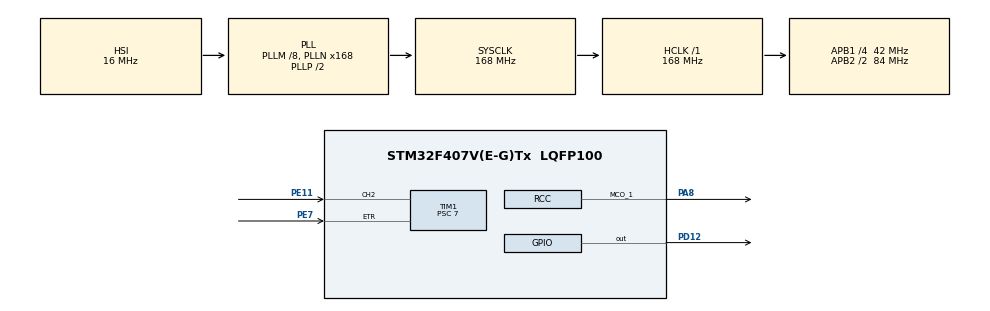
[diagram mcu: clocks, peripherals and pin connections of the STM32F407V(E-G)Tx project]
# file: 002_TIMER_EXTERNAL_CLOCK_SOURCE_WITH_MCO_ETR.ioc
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Mcu.Family=STM32F4
Mcu.Name=STM32F407V(E-G)Tx
Mcu.Package=LQFP100
NVIC.PriorityGroup=NVIC_PRIORITYGROUP_0
NVIC.TIM1_UP_TIM10_IRQn=true\:0\:0\:false\:false\:true\:true\:true
PA8.Mode=Clock-out-1
PA8.Signal=RCC_MCO_1
PD12.GPIO_Speed=GPIO_SPEED_FREQ_VERY_HIGH
PD12.Signal=GPIO_Output
PE11.Signal=S_TIM1_CH2
PE7.Signal=S_TIM1_ETR
PH0-OSC_IN.Mode=HSE-External-Oscillator
PH0-OSC_IN.Signal=RCC_OSC_IN
PH1-OSC_OUT.Mode=HSE-External-Oscillator
PH1-OSC_OUT.Signal=RCC_OSC_OUT
ProjectManager.HeapSize=0x200
ProjectManager.StackSize=0x400
ProjectManager.TargetToolchain=STM32CubeIDE
RCC.48MHZClocksFreq_Value=48000000
RCC.AHBFreq_Value=168000000
RCC.APB1CLKDivider=RCC_HCLK_DIV4
RCC.APB1Freq_Value=42000000
RCC.APB1TimFreq_Value=84000000
RCC.APB2CLKDivider=RCC_HCLK_DIV2
RCC.APB2Freq_Value=84000000
RCC.APB2TimFreq_Value=168000000
RCC.CortexFreq_Value=168000000
RCC.HCLKFreq_Value=168000000
RCC.HSE_VALUE=8000000
RCC.HSI_VALUE=16000000
RCC.LSE_VALUE=32768
RCC.PLLM=8
RCC.PLLN=168
RCC.PLLQ=7
RCC.RCC_MCO1Source=RCC_MCO1SOURCE_HSE
RCC.SYSCLKFreq_VALUE=168000000
RCC.SYSCLKSource=RCC_SYSCLKSOURCE_PLLCLK
RCC.VCOOutputFreq_Value=336000000
SH.S_TIM1_CH2.0=TIM1_CH2,TriggerSource_TI2FP2
SH.S_TIM1_ETR.0=TIM1_ETR,ClockSourceETR_Mode2
TIM1.AutoReloadPreload=TIM_AUTORELOAD_PRELOAD_DISABLE
TIM1.Period=19
TIM1.Prescaler=7
TIM1.TIM_MasterOutputTrigger=TIM_TRGO_RESET
VP_TIM1_VS_ControllerModeTrigger.Mode=Trigger Mode
board=STM32F407G-DISC1

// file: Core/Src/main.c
/* USER CODE BEGIN Header */
/**
  ******************************************************************************
  * @file           : main.c
  * @brief          : Main program body
  ******************************************************************************
  * @attention
  *
  * Copyright (c) 2021 STMicroelectronics.
  * All rights reserved.
  *
  * This software is licensed under terms that can be found in the LICENSE file
  * in the root directory of this software component.
  * If no LICENSE file comes with this software, it is provided AS-IS.
  *
  ******************************************************************************
  */
/* USER CODE END Header */
#include "main.h"

TIM_HandleTypeDef htim1;

void SystemClock_Config(void);
static void MX_GPIO_Init(void);
static void MX_TIM1_Init(void);

int main(void)
{

  /* MCU Configuration--------------------------------------------------------*/

  /* Reset of all peripherals, Initializes the Flash interface and the Systick. */
  HAL_Init();

  /* Configure the system clock */
  SystemClock_Config();

  /* Initialize all configured peripherals */
  MX_GPIO_Init();
  MX_TIM1_Init();
  /* USER CODE BEGIN 2 */
HAL_TIM_Base_Start_IT(&htim1);
  /* USER CODE END 2 */

  /* Infinite loop */
  while (1)
  {

  }
}

void SystemClock_Config(void)
{
  RCC_OscInitTypeDef RCC_OscInitStruct = {0};
  RCC_ClkInitTypeDef RCC_ClkInitStruct = {0};

  /** Configure the main internal regulator output voltage
  */
  __HAL_RCC_PWR_CLK_ENABLE();
  __HAL_PWR_VOLTAGESCALING_CONFIG(PWR_REGULATOR_VOLTAGE_SCALE1);
  /** Initializes the RCC Oscillators according to the specified parameters
  * in the RCC_OscInitTypeDef structure.
  */
  RCC_OscInitStruct.OscillatorType = RCC_OSCILLATORTYPE_HSI|RCC_OSCILLATORTYPE_HSE;
  RCC_OscInitStruct.HSEState = RCC_HSE_ON;
  RCC_OscInitStruct.HSIState = RCC_HSI_ON;
  RCC_OscInitStruct.HSICalibrationValue = RCC_HSICALIBRATION_DEFAULT;
  RCC_OscInitStruct.PLL.PLLState = RCC_PLL_ON;
  RCC_OscInitStruct.PLL.PLLSource = RCC_PLLSOURCE_HSI;
  RCC_OscInitStruct.PLL.PLLM = 8;
  RCC_OscInitStruct.PLL.PLLN = 168;
  RCC_OscInitStruct.PLL.PLLP = RCC_PLLP_DIV2;
  RCC_OscInitStruct.PLL.PLLQ = 7;
  if (HAL_RCC_OscConfig(&RCC_OscInitStruct) != HAL_OK)
  {
    Error_Handler();
  }
  /** Initializes the CPU, AHB and APB buses clocks
  */
  RCC_ClkInitStruct.ClockType = RCC_CLOCKTYPE_HCLK|RCC_CLOCKTYPE_SYSCLK
                              |RCC_CLOCKTYPE_PCLK1|RCC_CLOCKTYPE_PCLK2;
  RCC_ClkInitStruct.SYSCLKSource = RCC_SYSCLKSOURCE_PLLCLK;
  RCC_ClkInitStruct.AHBCLKDivider = RCC_SYSCLK_DIV1;
  RCC_ClkInitStruct.APB1CLKDivider = RCC_HCLK_DIV4;
  RCC_ClkInitStruct.APB2CLKDivider = RCC_HCLK_DIV2;

  if (HAL_RCC_ClockConfig(&RCC_ClkInitStruct, FLASH_LATENCY_5) != HAL_OK)
  {
    Error_Handler();
  }
  HAL_RCC_MCOConfig(RCC_MCO1, RCC_MCO1SOURCE_HSE, RCC_MCODIV_1);
}

static void MX_TIM1_Init(void)
{

  TIM_ClockConfigTypeDef sClockSourceConfig = {0};
  TIM_SlaveConfigTypeDef sSlaveConfig = {0};
  TIM_MasterConfigTypeDef sMasterConfig = {0};

  htim1.Instance = TIM1;
  htim1.Init.Prescaler = 7;
  htim1.Init.CounterMode = TIM_COUNTERMODE_UP;
  htim1.Init.Period = 199;
  htim1.Init.ClockDivision = TIM_CLOCKDIVISION_DIV1;
  htim1.Init.RepetitionCounter = 0;
  htim1.Init.AutoReloadPreload = TIM_AUTORELOAD_PRELOAD_DISABLE;
  if (HAL_TIM_Base_Init(&htim1) != HAL_OK)
  {
    Error_Handler();
  }
  sClockSourceConfig.ClockSource = TIM_CLOCKSOURCE_ETRMODE2;
  sClockSourceConfig.ClockPolarity = TIM_CLOCKPOLARITY_NONINVERTED;
  sClockSourceConfig.ClockPrescaler = TIM_CLOCKPRESCALER_DIV1;
  sClockSourceConfig.ClockFilter = 0;
  if (HAL_TIM_ConfigClockSource(&htim1, &sClockSourceConfig) != HAL_OK)
  {
    Error_Handler();
  }
  sSlaveConfig.SlaveMode = TIM_SLAVEMODE_TRIGGER;
  sSlaveConfig.InputTrigger = TIM_TS_TI2FP2;
  sSlaveConfig.TriggerPolarity = TIM_TRIGGERPOLARITY_RISING;
  sSlaveConfig.TriggerFilter = 0;
  if (HAL_TIM_SlaveConfigSynchro(&htim1, &sSlaveConfig) != HAL_OK)
  {
    Error_Handler();
  }
  sMasterConfig.MasterOutputTrigger = TIM_TRGO_RESET;
  sMasterConfig.MasterSlaveMode = TIM_MASTERSLAVEMODE_DISABLE;
  if (HAL_TIMEx_MasterConfigSynchronization(&htim1, &sMasterConfig) != HAL_OK)
  {
    Error_Handler();
  }

}

static void MX_GPIO_Init(void)
{
  GPIO_InitTypeDef GPIO_InitStruct = {0};

  /* GPIO Ports Clock Enable */
  __HAL_RCC_GPIOH_CLK_ENABLE();
  __HAL_RCC_GPIOE_CLK_ENABLE();
  __HAL_RCC_GPIOD_CLK_ENABLE();
  __HAL_RCC_GPIOA_CLK_ENABLE();

  /*Configure GPIO pin Output Level */
  HAL_GPIO_WritePin(GPIOD, GPIO_PIN_12, GPIO_PIN_RESET);

  /*Configure GPIO pin : PD12 */
  GPIO_InitStruct.Pin = GPIO_PIN_12;
  GPIO_InitStruct.Mode = GPIO_MODE_OUTPUT_PP;
  GPIO_InitStruct.Pull = GPIO_NOPULL;
  GPIO_InitStruct.Speed = GPIO_SPEED_FREQ_VERY_HIGH;
  HAL_GPIO_Init(GPIOD, &GPIO_InitStruct);

  /*Configure GPIO pin : PA8 */
  GPIO_InitStruct.Pin = GPIO_PIN_8;
  GPIO_InitStruct.Mode = GPIO_MODE_AF_PP;
  GPIO_InitStruct.Pull = GPIO_NOPULL;
  GPIO_InitStruct.Speed = GPIO_SPEED_FREQ_LOW;
  GPIO_InitStruct.Alternate = GPIO_AF0_MCO;
  HAL_GPIO_Init(GPIOA, &GPIO_InitStruct);

}

/* USER CODE BEGIN 4 */
void HAL_TIM_PeriodElapsedCallback(TIM_HandleTypeDef *htim)
{
	// This callback is automatically called by the HAL on the UEV event
	if(htim->Instance == TIM1)
	{
		 HAL_GPIO_TogglePin(GPIOD, GPIO_PIN_12);
	}

}
/* USER CODE END 4 */

void Error_Handler(void)
{
  __disable_irq();
  while (1)
  {
  }
}
